# dphy_rx_K3_DPHY_WRAP_REGS_30111000h register map
Vendor: Texas Instruments
Peripheral module from a debugger description file (folder am62D).
Registers are 32-bit, access per field, reset 0x0 unless marked. A register's access mark holds for its fields unless they carry their own. Offsets are as the file gives them; lines under a group give offsets from that group; [hi:lo] are bit positions; {n}, {i} and the like mark numbered series; 'fields as' and 'values as' point back to an identical list; <NAME> marks a mode.

## k3_dphy_wrap_regs
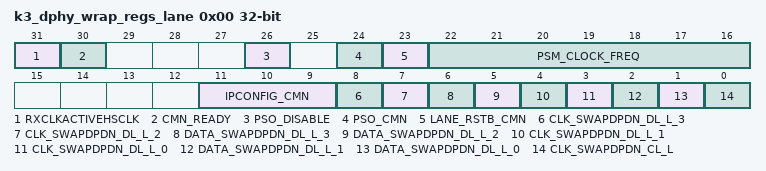
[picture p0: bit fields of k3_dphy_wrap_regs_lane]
0x00 k3_dphy_wrap_regs_lane — lane control and status
  [31] RXCLKACTIVEHSCLK ro — Receiver high speed clock active: Driven active when the receiver high speed clock is active. 1'b0: Receiver high speed clock not active, 1'b1: Receiver high speed clock active Reset Source: rst_n
  [30] CMN_READY ro — Common ready indication: Indicates the completion of the startup process of the common module. Once this signal is driven active, the PMA lanes may be released from reset. 1'b0 : Indicates that the startup process for the common components is not complete. This will be the case for both the power on reset sequence, and when the common is transitioning into and out of the low power modes. 1'b1: Indicates that the startup process for the common components is complete and the common is ready. Note that this is a function of the PLL being enabled and locked. Reset Source: rst_n
  [26] PSO_DISABLE rw — Disable power shut off: Disables the ability to switch off the analog switched power islands in the lane when in the ultra low power state. 1'b0: Power islands are switched off and on under the normal control of the escape mode process. 1'b1: Power island shutoff functions disabled, and switched power islands forced to the enabled state. Reset Source: rst_n
  [24] PSO_CMN rw — Disable power shut off: Power Shutoff signal for CMN 1 : CMN is power OFF 0 : CMN is power ON Reset Source: rst_n
  [23] LANE_RSTB_CMN rw — SW reset for CMN. 0:asserted 1:released Reset Source: rst_n
  [22:16] PSM_CLOCK_FREQ rw — PMA state machine clock frequency divider control: This signal specifies a divider value used to create an internal divided clock that is a function of the psm_clock clock. This signal must be driven with a value such that the frequency of the divided clock is 1 MHz. In the case where it is not possible for the divided clock to be exactly 1 MHz, a value should be selected that results in the clock frequency being the closest to 1 MHz. The following specifies the divider settings that the values of this signal correspond to. # 8'h00 : Reserved # 8'h01 : Div 1 # 8'h02 : Div 2 # 8'h03 : Div 3 # 8'h04 : Div 4 ... # 8'hFF : Div 255 Note: PSM clock has a maximum frequency of 100 MHz. values beyond 100 should not be programmed Reset Source: rst_n
  [11:9] IPCONFIG_CMN rw — This signal decides which clock lane acts as master clock lane to all data lanes. Needed only for RX IP. Bit[2]: Reserved CASE {Bit[1],Bit[0]}: 00: Left RX clk lane provides clock to all left and right data lanes. 01: Left RX clk lane provides clock to all right data lanes, Right RX clk lane provides clock to all left data lanes. 10: Right RX clk lane provides clock to all right data lanes, Left RX clk lane provides clock to all left data lanes. 11: Right RX clk lane provides clock to all left and right data lanes. Reset Source: rst_n
  [8] CLK_SWAPDPDN_DL_L_3 rw — Swap DP and DN: When enabled, the rx_p and rx_m differential pins will be swapped. 1'b0: Not swapped 1'b1: Swapped Reset Source: rst_n
  [7] CLK_SWAPDPDN_DL_L_2 rw — Swap DP and DN: When enabled, the rx_p and rx_m differential pins will be swapped. 1'b0: Not swapped 1'b1: Swapped Reset Source: rst_n
  [6] DATA_SWAPDPDN_DL_L_3 rw — Swap DP and DN: When enabled, the rx_p and rx_m differential pins will be swapped. 1'b0: Not swapped 1'b1: Swapped Reset Source: rst_n
  [5] DATA_SWAPDPDN_DL_L_2 rw — Swap DP and DN: When enabled, the rx_p and rx_m differential pins will be swapped. 1'b0: Not swapped 1'b1: Swapped Reset Source: rst_n
  [4] CLK_SWAPDPDN_DL_L_1 rw — Swap DP and DN: When enabled, the rx_p and rx_m differential pins will be swapped. 1'b0: Not swapped 1'b1: Swapped Reset Source: rst_n
  [3] CLK_SWAPDPDN_DL_L_0 rw — Swap DP and DN: When enabled, the rx_p and rx_m differential pins will be swapped. 1'b0: Not swapped 1'b1: Swapped Reset Source: rst_n
  [2] DATA_SWAPDPDN_DL_L_1 rw — Swap DP and DN: When enabled, the rx_p and rx_m differential pins will be swapped. 1'b0: Not swapped 1'b1: Swapped Reset Source: rst_n
  [1] DATA_SWAPDPDN_DL_L_0 rw — Swap DP and DN: When enabled, the rx_p and rx_m differential pins will be swapped. 1'b0: Not swapped 1'b1: Swapped Reset Source: rst_n
  [0] CLK_SWAPDPDN_CL_L rw — Swap DP and DN: When enabled, the rx_p and rx_m differential pins will be swapped. 1'b0: Not swapped 1'b1: Swapped Reset Source: rst_n
